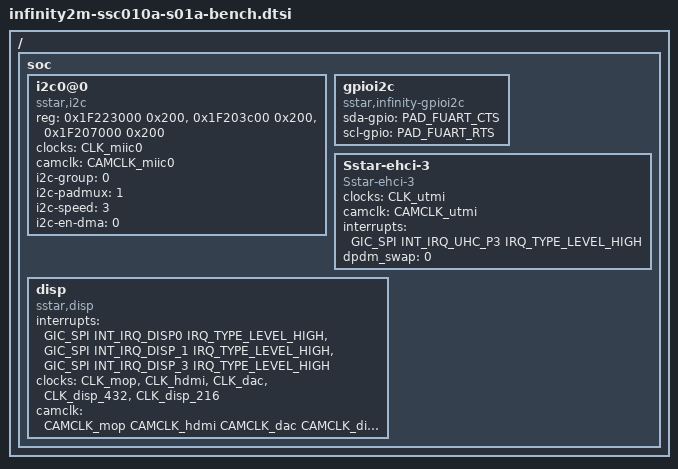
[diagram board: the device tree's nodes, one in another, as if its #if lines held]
/*
* infinity2m-scc010a-s01a-s.dts - Sigmastar
*
* Copyright (C) 2018 Sigmastar Technology Corp.
*
* Author: Joe.Su <joe.su@sigmastar.com.tw>
*
* This software is licensed under the terms of the GNU General Public
* License version 2, as published by the Free Software Foundation, and
* may be copied, distributed, and modified under those terms.
*
* This program is distributed in the hope that it will be useful,
* but WITHOUT ANY WARRANTY; without even the implied warranty of
* MERCHANTABILITY or FITNESS FOR A PARTICULAR PURPOSE.  See the
* GNU General Public License for more details.
*
*/

/ {
    soc {

/*
        cpufreq {
            vid-num = /bits/ 8 <2>;
            vid-gpios = /bits/ 8 <PAD_UART1_RX PAD_SAR_GPIO1>;
        };
*/

       i2c0@0{
            compatible = "sstar,i2c";
            reg = <0x1F223000 0x200>,<0x1F203c00 0x200>,<0x1F207000 0x200>;
                #address-cells = <1>;
                #size-cells = <0>;
            clocks = <&CLK_miic0>;
#ifdef CONFIG_CAM_CLK
      camclk = <CAMCLK_miic0 >;
#endif
            i2c-group = <0>;
            /*
             * padmux: 1 -> PAD_HDMITX_SCL, PAD_HDMITX_SDA
             *         2 -> PAD_TTL1, PAD_TTL2
             *         3 -> PAD_TTL14, PAD_TTL15
            */
            i2c-padmux = <1>;
            /*
              *  speed: 0 -> HWI2C_HIGH(high speed: 400 KHz)
              *         1 -> HWI2C_NORMAL(normal speed: 300 KHz)
              *         2 -> HWI2C_SLOW(slow speed: 200 KHz)
              *         3 -> HWI2C_VSLOW(very slow: 100 KHz)
              *         4 -> HWI2C_USLOW(ultra slow: 50 KHz)
              *         5 -> HWI2C_UVSLOW(ultra-very slow: 25 KHz)
              */
            i2c-speed = <3>;
            i2c-en-dma = <0>;  // 0: disable; 1: enable;
            status = "ok";
        };
/*
        i2c1@1{
            compatible = "sstar,i2c";
            reg = <0x1F223200 0x200>,<0x1F203c00 0x200>,<0x1F207000 0x200>;
                #address-cells = <1>;
                #size-cells = <0>;
            clocks = <&CLK_miic1>;
#ifdef CONFIG_CAM_CLK
      camclk = <CAMCLK_miic1 >;
#endif
            i2c-group = <1>;
*/
            /*
             * padmux: 2 -> PAD_HDMITX_SCL, PAD_HDMITX_SDA
             *         3 -> PAD_FUART_CTS, PAD_FUART_RTS
             *         4 -> PAD_TTL22, PAD_TTL23
             *         5 -> PAD_SD_CLK, PAD_SD_CMD
            */
//            i2c-padmux = <4>;
             /*
              *  speed: 0 -> HWI2C_HIGH(high speed: 400 KHz)
              *         1 -> HWI2C_NORMAL(normal speed: 300 KHz)
              *         2 -> HWI2C_SLOW(slow speed: 200 KHz)
              *         3 -> HWI2C_VSLOW(very slow: 100 KHz)
              *         4 -> HWI2C_USLOW(ultra slow: 50 KHz)
              *         5 -> HWI2C_UVSLOW(ultra-very slow: 25 KHz)
              */
/*
            i2c-speed = <1>;
            i2c-en-dma = <0>;  // 0: disable; 1: enable; for hdmi: cannot be enabled
            status = "ok";
        };
*/
        gpioi2c {
            compatible = "sstar,infinity-gpioi2c";
            sda-gpio = <PAD_FUART_CTS>;
            scl-gpio = <PAD_FUART_RTS>;
            status = "ok";
        };

        Sstar-ehci-3 {
            compatible = "Sstar-ehci-3";
            clocks = <&CLK_utmi>;
#ifdef CONFIG_CAM_CLK
      camclk = <CAMCLK_utmi >;
#endif
            interrupts = <GIC_SPI INT_IRQ_UHC_P3 IRQ_TYPE_LEVEL_HIGH>;
            dpdm_swap=<0>;
            //power-enable-pad = <PAD_FUART_TX>;
            status = "ok";
        };

        disp: disp {
            compatible = "sstar,disp";
            status = "ok";
            interrupts = <GIC_SPI INT_IRQ_DISP0 IRQ_TYPE_LEVEL_HIGH>, <GIC_SPI INT_IRQ_DISP_1 IRQ_TYPE_LEVEL_HIGH>, <GIC_SPI INT_IRQ_DISP_3 IRQ_TYPE_LEVEL_HIGH>;
            clocks = <&CLK_mop>, <&CLK_hdmi>, <&CLK_dac>, <&CLK_disp_432>, <&CLK_disp_216>;
#ifdef CONFIG_CAM_CLK
      camclk = <CAMCLK_mop CAMCLK_hdmi CAMCLK_dac CAMCLK_disp_432 CAMCLK_disp_216 >;
#endif
            clock-names = "CLK_mop", "CLK_hdmi", "CLK_dac", "CLK_disp_432", "CLK_disp_216";
            //Reg = <0x1F224000 0x200>;
        };

    };

};
